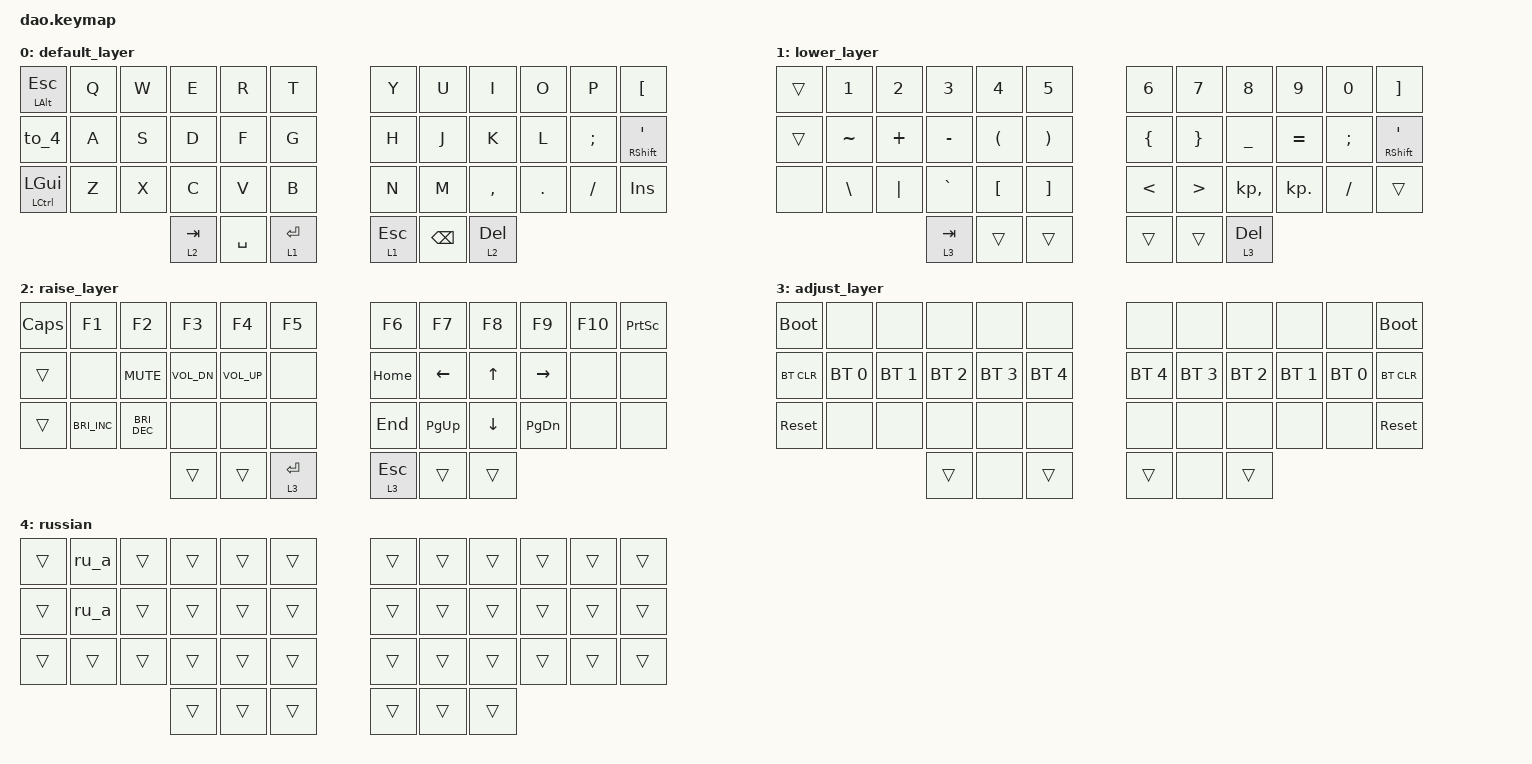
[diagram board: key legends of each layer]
#include <behaviors.dtsi>
#include <dt-bindings/zmk/bt.h>
#include <dt-bindings/zmk/keys.h>

#define HOST_OS 0

#include "../zmk-nodefree-config/helper.h"
#include "../zmk-nodefree-config/international_chars/russian.dtsi"


#define DEF 0
#define LWR 1
#define RSE 2
#define ADJ 3

&lt { quick_tap_ms = <200>; };

&mt { quick_tap_ms = <200>; };

/ {
    chosen {
        zmk,matrix_transform = &default_transform;

        // zmk,matrix_transform = &extra_keys_transform;
    };
};

/ {
    behaviors {
        to_4: behavior_to_4 {
            compatible = "zmk,behavior-hold-tap";
            #binding-cells = <2>;
            flavor = "tap-preferred";
            tapping-term-ms = <200>;
            quick-tap-ms = <200>;
            require-prior-idle-ms = <125>;
            bindings = <&kp LEFT_SHIFT>, <&tog 4>;
        };
    };
};

/ {
    combos {
        compatible = "zmk,combos";

        language_combo {
            bindings = <&kp LS(LEFT_ALT)>;
            key-positions = <12 37>;
        };

        altTab {
            bindings = <&kp LA(TAB)>;
            key-positions = <12 36>;
        };

        ctrlshiftesc {
            bindings = <&kp LS(LC(ESCAPE))>;
            key-positions = <0 12 24>;
        };
    };


    macros {
        language_switcher: language_switcher {
            compatible = "zmk,behavior-macro";
            #binding-cells = <0>;
            bindings =
                <&macro_press>,
                <&kp LALT>,
                <&macro_tap>,
                <&kp LEFT_SHIFT>,
                <&macro_release>,
                <&kp LALT>;

            label = "LANGUAGE_SWITCHER";
        };

        dot: dot {
            compatible = "zmk,behavior-macro";
            #binding-cells = <0>;
            bindings =
                <&macro_press>,
                <&kp LALT>,
                <&macro_tap>,
                <&kp KP_N4 &kp KP_N6>,
                <&macro_release>,
                <&kp LALT>;

            label = "DOT";
        };
    };

    keymap {
        compatible = "zmk,keymap";

        default_layer {
            bindings = <
&mt LEFT_ALT ESCAPE            &kp Q  &kp W  &kp E      &kp R      &kp T        &kp Y         &kp U          &kp I         &kp O    &kp P     &kp LBKT
&to_4                          &kp A  &kp S  &kp D      &kp F      &kp G        &kp H         &kp J          &kp K         &kp L    &kp SEMI  &mt RIGHT_SHIFT SQT
&mt LCTRL LEFT_GUI             &kp Z  &kp X  &kp C      &kp V      &kp B        &kp N         &kp M          &kp COMMA     &kp DOT  &kp FSLH  &kp INSERT
                                             &lt 2 TAB  &kp SPACE  &lt 1 ENTER  &lt 1 ESCAPE  &kp BACKSPACE  &lt 2 DELETE
            >;
        };

        lower_layer {
            bindings = <
&trans  &kp N1         &kp N2    &kp N3     &kp N4                &kp N5                 &kp N6          &kp N7            &kp N8          &kp N9      &kp N0         &kp RIGHT_BRACKET
&trans  &kp TILDE      &kp PLUS  &kp MINUS  &kp LEFT_PARENTHESIS  &kp RIGHT_PARENTHESIS  &kp LEFT_BRACE  &kp RIGHT_BRACE   &kp UNDERSCORE  &kp EQUAL   &kp SEMICOLON  &mt RIGHT_SHIFT SINGLE_QUOTE
&none   &kp BACKSLASH  &kp PIPE  &kp GRAVE  &kp LEFT_BRACKET      &kp RIGHT_BRACKET      &kp LESS_THAN   &kp GREATER_THAN  &kp KP_COMMA    &kp KP_DOT  &kp SLASH      &trans
                                 &lt 3 TAB  &trans                &trans                 &trans          &trans            &lt 3 DEL
            >;
        };

        raise_layer {
            bindings = <
&kp CAPSLOCK  &kp F1                &kp F2                &kp F3        &kp F4           &kp F5     &kp F6     &kp F7       &kp F8          &kp F9         &kp F10  &kp PRINTSCREEN
&trans        &none                 &kp C_MUTE            &kp C_VOL_DN  &kp C_VOLUME_UP  &none      &kp HOME   &kp LEFT     &kp UP_ARROW    &kp RIGHT      &none    &none
&trans        &kp C_BRIGHTNESS_INC  &kp C_BRIGHTNESS_DEC  &none         &none            &none      &kp END    &kp PAGE_UP  &kp DOWN_ARROW  &kp PAGE_DOWN  &none    &none
                                                          &trans        &trans           &lt 3 RET  &lt 3 ESC  &trans       &trans
            >;
        };

        adjust_layer {
            bindings = <
&bootloader  &none         &none         &none         &none         &none         &none         &none         &none         &none         &none         &bootloader
&bt BT_CLR   &bt BT_SEL 0  &bt BT_SEL 1  &bt BT_SEL 2  &bt BT_SEL 3  &bt BT_SEL 4  &bt BT_SEL 4  &bt BT_SEL 3  &bt BT_SEL 2  &bt BT_SEL 1  &bt BT_SEL 0  &bt BT_CLR
&sys_reset   &none         &none         &none         &none         &none         &none         &none         &none         &none         &none         &sys_reset
                                         &trans        &none         &trans        &trans        &none         &trans
            >;
        };

        russian {
            bindings = <
&trans  &ru_a   &trans  &trans  &trans  &trans  &trans  &trans  &trans  &trans  &trans  &trans
&trans  &ru_a   &trans  &trans  &trans  &trans  &trans  &trans  &trans  &trans  &trans  &trans
&trans  &trans  &trans  &trans  &trans  &trans  &trans  &trans  &trans  &trans  &trans  &trans
                        &trans  &trans  &trans  &trans  &trans  &trans
            >;
        };
    };
};
